# COMPUTE_CLUSTER0_MSMC_ECC_AGGR2 register map
Vendor: Texas Instruments
Peripheral module from a debugger description file (folder J7ES).
Registers are 32-bit, access not given, reset 0x0 unless marked. A register's access mark holds for its fields unless they carry their own. Offsets are as the file gives them; lines under a group give offsets from that group; [hi:lo] are bit positions; {n}, {i} and the like mark numbered series; 'fields as' and 'values as' point back to an identical list; <NAME> marks a mode.

## COMPUTE_CLUSTER0_MSMC_ECC_AGGR2
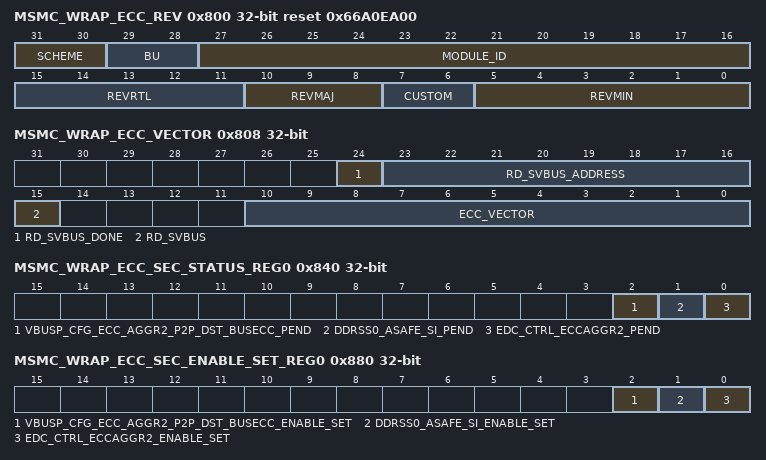
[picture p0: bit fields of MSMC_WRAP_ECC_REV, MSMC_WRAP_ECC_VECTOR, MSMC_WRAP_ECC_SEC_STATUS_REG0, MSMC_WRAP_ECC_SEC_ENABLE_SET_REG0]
0x800 MSMC_WRAP_ECC_REV ro reset 0x66A0EA00 — Revision parameters
  [31:30] SCHEME
  [29:28] BU
  [27:16] MODULE_ID
  [15:11] REVRTL — RTL version
  [10:8] REVMAJ — Major version
  [7:6] CUSTOM — Custom version
  [5:0] REVMIN — Minor version
0x808 MSMC_WRAP_ECC_VECTOR — ECC Vector Register
  [24] RD_SVBUS_DONE — Status to indicate if read on serial VBUS is complete, write of any value will clear this bit. (access RW1C)
  [23:16] RD_SVBUS_ADDRESS rw — Read address
  [15] RD_SVBUS — Write 1 to trigger a read on the serial VBUS (access RW1S)
  [10:0] ECC_VECTOR rw — Value written to select the corresponding ECC RAM for control or status
0x80C MSMC_WRAP_ECC_STAT ro reset 0x3 — Misc Status
  [10:0] NUM_RAMS — Indicates the number of RAMS serviced by the ECC aggregator
0x810 MSMC_WRAP_ECC_RESERVED_SVBUS_y rw — Reference other documents that contain the ECC RAM wrapper and EDC controller serial vbus register sets. Offset = 810h + (y * 4h); where y = 0h to 7h
  [31:0] DATA — Serial VBUS register data
0x83C MSMC_WRAP_ECC_SEC_EOI_REG — EOI Register The EOI register is used to re-trigger the pulse interrupt signal to ensure that any nested interrupt events are serviced. The software interrupt handler must write to the EOI register at the end of the current interrupt processing routine, so that new events can re-trigger the pulse interrupt signal again. For level interrupt signals the EOI register is not functional and must not be used.
  [0] EOI_WR — EOI Register (access RW1S)
0x840 MSMC_WRAP_ECC_SEC_STATUS_REG0 — Interrupt Status Register 0
  [2] VBUSP_CFG_ECC_AGGR2_P2P_DST_BUSECC_PEND — Interrupt Pending Status for vbusp_cfg_ecc_aggr2_p2p_dst_busecc_pend (access RW1S)
  [1] DDRSS0_ASAFE_SI_PEND — Interrupt Pending Status for ddrss0_asafe_si_pend (access RW1S)
  [0] EDC_CTRL_ECCAGGR2_PEND — Interrupt Pending Status for edc_ctrl_eccaggr2_pend (access RW1S)
0x880 MSMC_WRAP_ECC_SEC_ENABLE_SET_REG0 — Interrupt Enable Set Register 0
  [2] VBUSP_CFG_ECC_AGGR2_P2P_DST_BUSECC_ENABLE_SET — Interrupt Enable Set Register for vbusp_cfg_ecc_aggr2_p2p_dst_busecc_pend (access RW1S)
  [1] DDRSS0_ASAFE_SI_ENABLE_SET — Interrupt Enable Set Register for ddrss0_asafe_si_pend (access RW1S)
  [0] EDC_CTRL_ECCAGGR2_ENABLE_SET — Interrupt Enable Set Register for edc_ctrl_eccaggr2_pend (access RW1S)
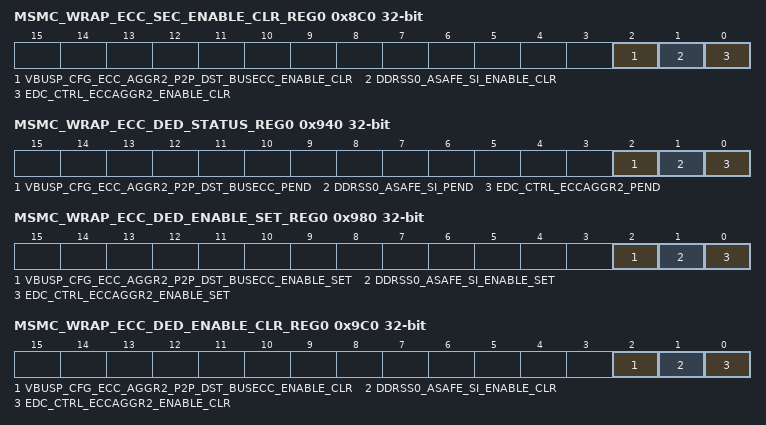
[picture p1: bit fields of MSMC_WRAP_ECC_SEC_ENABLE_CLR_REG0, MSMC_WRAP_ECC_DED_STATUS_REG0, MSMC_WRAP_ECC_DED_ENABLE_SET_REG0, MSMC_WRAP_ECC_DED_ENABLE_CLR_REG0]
0x8C0 MSMC_WRAP_ECC_SEC_ENABLE_CLR_REG0 — Interrupt Enable Clear Register 0
  [2] VBUSP_CFG_ECC_AGGR2_P2P_DST_BUSECC_ENABLE_CLR — Interrupt Enable Clear Register for vbusp_cfg_ecc_aggr2_p2p_dst_busecc_pend (access RW1C)
  [1] DDRSS0_ASAFE_SI_ENABLE_CLR — Interrupt Enable Clear Register for ddrss0_asafe_si_pend (access RW1C)
  [0] EDC_CTRL_ECCAGGR2_ENABLE_CLR — Interrupt Enable Clear Register for edc_ctrl_eccaggr2_pend (access RW1C)
0x93C MSMC_WRAP_ECC_DED_EOI_REG — EOI Register The EOI register is used to re-trigger the pulse interrupt signal to ensure that any nested interrupt events are serviced. The software interrupt handler must write to the EOI register at the end of the current interrupt processing routine, so that new events can re-trigger the pulse interrupt signal again. For level interrupt signals the EOI register is not functional and must not be used.
  [0] EOI_WR — EOI Register (access RW1S)
0x940 MSMC_WRAP_ECC_DED_STATUS_REG0 — Interrupt Status Register 0
  fields as MSMC_WRAP_ECC_SEC_STATUS_REG0
0x980 MSMC_WRAP_ECC_DED_ENABLE_SET_REG0 — Interrupt Enable Set Register 0
  fields as MSMC_WRAP_ECC_SEC_ENABLE_SET_REG0
0x9C0 MSMC_WRAP_ECC_DED_ENABLE_CLR_REG0 — Interrupt Enable Clear Register 0
  fields as MSMC_WRAP_ECC_SEC_ENABLE_CLR_REG0
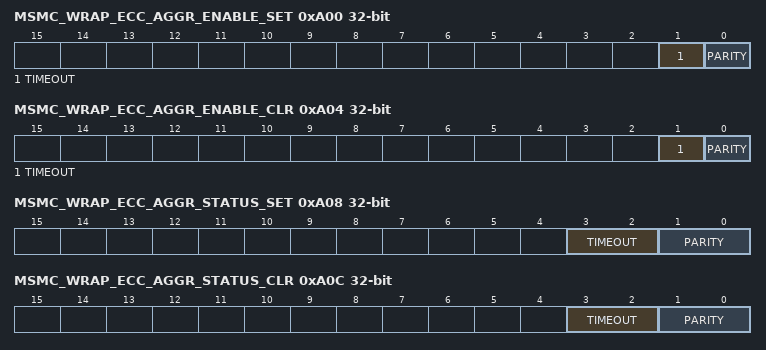
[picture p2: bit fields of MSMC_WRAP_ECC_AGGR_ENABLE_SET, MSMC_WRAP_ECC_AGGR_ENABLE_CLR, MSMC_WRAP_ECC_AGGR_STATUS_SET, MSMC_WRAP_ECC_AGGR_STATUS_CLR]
0xA00 MSMC_WRAP_ECC_AGGR_ENABLE_SET — AGGR interrupt enable set Register
  [1] TIMEOUT — interrupt enable set for svbus timeout errors (access RW1S)
  [0] PARITY — interrupt enable set for parity errors (access RW1S)
0xA04 MSMC_WRAP_ECC_AGGR_ENABLE_CLR — AGGR interrupt enable clear Register
  [1] TIMEOUT — interrupt enable clear for svbus timeout errors (access RW1C)
  [0] PARITY — interrupt enable clear for parity errors (access RW1C)
0xA08 MSMC_WRAP_ECC_AGGR_STATUS_SET — AGGR interrupt status set Register
  [3:2] TIMEOUT — interrupt status set for svbus timeout errors (access RWincr)
  [1:0] PARITY — interrupt status set for parity errors (access RWincr)
0xA0C MSMC_WRAP_ECC_AGGR_STATUS_CLR — AGGR interrupt status clear Register
  [3:2] TIMEOUT — interrupt status clear for svbus timeout errors (access RWdecr)
  [1:0] PARITY — interrupt status clear for parity errors (access RWdecr)
